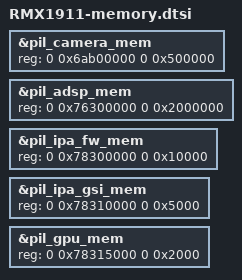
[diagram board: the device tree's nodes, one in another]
/*
 * Copyright (c) 2019, The Linux Foundation. All rights reserved.
 *
 * This program is free software; you can redistribute it and/or modify
 * it under the terms of the GNU General Public License version 2 and
 * only version 2 as published by the Free Software Foundation.
 *
 * This program is distributed in the hope that it will be useful,
 * but WITHOUT ANY WARRANTY; without even the implied warranty of
 * MERCHANTABILITY or FITNESS FOR A PARTICULAR PURPOSE.  See the
 * GNU General Public License for more details.
 */

&pil_camera_mem {
	reg = <0 0x6ab00000 0 0x500000>;
};

&pil_adsp_mem {
	reg = <0 0x76300000 0 0x2000000>;
};

&pil_ipa_fw_mem {
	reg = <0 0x78300000 0 0x10000>;
};

&pil_ipa_gsi_mem {
	reg = <0 0x78310000 0 0x5000>;
};

&pil_gpu_mem {
	reg = <0 0x78315000 0 0x2000>;
};
